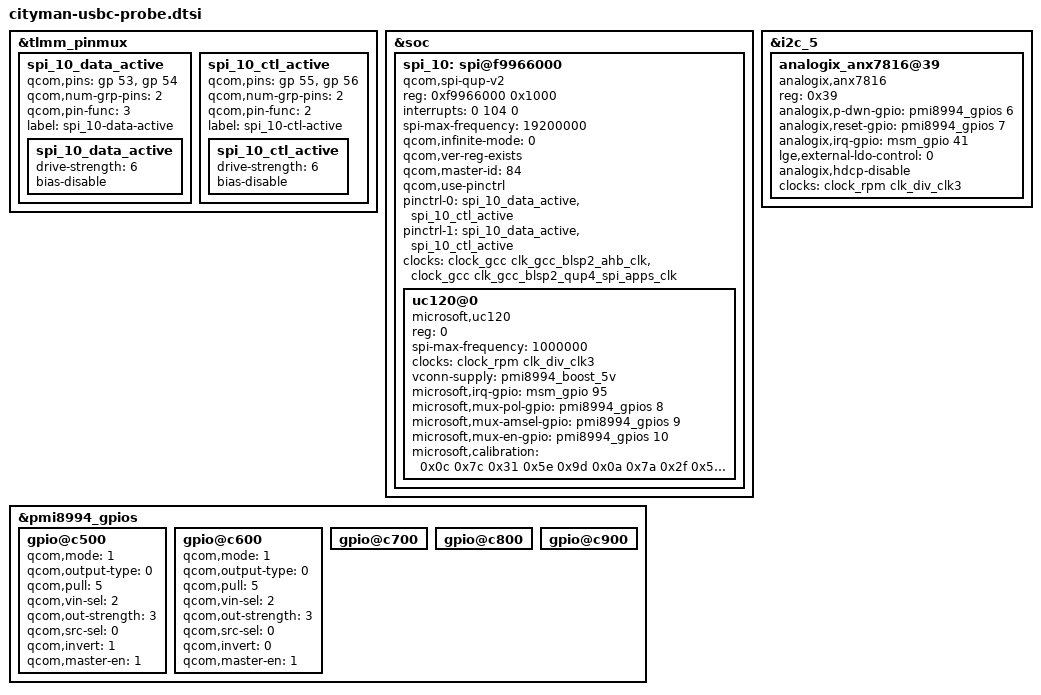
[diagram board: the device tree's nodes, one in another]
/*
 * USB-C path of the Lumia 950 XL, from the Windows SSDT:
 *  - UC120 (Lattice iCE5LP2K, MSHW1006): Type-C/PD PHY on SPI10 CS0,
 *    driven by drivers/misc/uc120.c (charging current, USB host, PD and
 *    DisplayPort alternate mode);
 *  - mux (MSHW1009): PMI8994 GPIO 5, 8, 9, 10;
 *  - Analogix ANX7816 (MSHW1007): HDMI to DisplayPort bridge on I2C11,
 *    power PMI8994 GPIO 6/7.
 * The file name is kept from the first probing branch.
 */

&tlmm_pinmux {
	spi_10_data_active {
		/* MOSI, MISO */
		qcom,pins = <&gp 53>, <&gp 54>;
		qcom,num-grp-pins = <2>;
		qcom,pin-func = <3>;
		label = "spi_10-data-active";
		spi_10_data_active: spi_10_data_active {
			drive-strength = <6>;
			bias-disable;
		};
	};

	spi_10_ctl_active {
		/* CS0, CLK */
		qcom,pins = <&gp 55>, <&gp 56>;
		qcom,num-grp-pins = <2>;
		qcom,pin-func = <2>;
		label = "spi_10-ctl-active";
		spi_10_ctl_active: spi_10_ctl_active {
			drive-strength = <6>;
			bias-disable;
		};
	};
};

&soc {
	spi_10: spi@f9966000 { /* BLSP2 QUP4 */
		compatible = "qcom,spi-qup-v2";
		#address-cells = <1>;
		#size-cells = <0>;
		reg-names = "spi_physical";
		reg = <0xf9966000 0x1000>;
		interrupt-names = "spi_irq";
		interrupts = <0 104 0>;
		spi-max-frequency = <19200000>;
		qcom,infinite-mode = <0>;
		qcom,ver-reg-exists;
		qcom,master-id = <84>;
		qcom,use-pinctrl;
		pinctrl-names = "spi_default", "spi_sleep";
		pinctrl-0 = <&spi_10_data_active &spi_10_ctl_active>;
		pinctrl-1 = <&spi_10_data_active &spi_10_ctl_active>;
		clock-names = "iface_clk", "core_clk";
		clocks = <&clock_gcc clk_gcc_blsp2_ahb_clk>,
			 <&clock_gcc clk_gcc_blsp2_qup4_spi_apps_clk>;

		/*
		 * UC120 Type-C/PD PHY. Calibration: MMO/ice5lp_2k_cal.bin of
		 * the DPP partition (v2 file, bytes 1..10); the driver falls
		 * back to the nominal thresholds without it. IRQ on TLMM 95.
		 * Mux as TypeCMux.sys: PMI8994 GPIO 8 POL, 9 AMSEL, 10 EN.
		 * VCONN from BOOST1_B as the Windows PEP.
		 */
		uc120@0 {
			compatible = "microsoft,uc120";
			reg = <0>;
			spi-max-frequency = <1000000>;
			clock-names = "xtal";
			clocks = <&clock_rpm clk_div_clk3>;
			vconn-supply = <&pmi8994_boost_5v>;
			microsoft,irq-gpio = <&msm_gpio 95 0>;
			microsoft,mux-pol-gpio = <&pmi8994_gpios 8 0>;
			microsoft,mux-amsel-gpio = <&pmi8994_gpios 9 0>;
			microsoft,mux-en-gpio = <&pmi8994_gpios 10 0>;
			microsoft,calibration = /bits/ 8 <0x0c 0x7c 0x31 0x5e 0x9d
							  0x0a 0x7a 0x2f 0x5c 0x9b>;
		};
	};
};

&pmi8994_gpios {
	/*
	 * GPIO 6 and 7 as the Windows PEP drives them for the mux (CPSW):
	 * CMOS output, VIN2 (1.8 V), high strength. Boot in the "USB" state
	 * (P-state 1: GPIO 6 high, GPIO 7 low); the video states turn GPIO 6
	 * low and GPIO 7 high together with PM8994 DIV_CLK3.
	 */
	gpio@c500 {	/* GPIO 6 */
		qcom,mode = <1>;
		qcom,output-type = <0>;
		qcom,pull = <5>;
		qcom,vin-sel = <2>;
		qcom,out-strength = <3>;
		qcom,src-sel = <0>;
		qcom,invert = <1>;	/* constant high */
		qcom,master-en = <1>;
		status = "okay";
	};
	gpio@c600 {	/* GPIO 7: Analogix power/reset */
		qcom,mode = <1>;
		qcom,output-type = <0>;
		qcom,pull = <5>;
		qcom,vin-sel = <2>;
		qcom,out-strength = <3>;
		qcom,src-sel = <0>;
		qcom,invert = <0>;	/* constant low */
		qcom,master-en = <1>;
		status = "okay";
	};
	gpio@c700 { status = "okay"; };	/* GPIO 8: mux */
	gpio@c800 { status = "okay"; };	/* GPIO 9: mux */
	gpio@c900 { status = "okay"; };	/* GPIO 10: mux */
};

/*
 * Analogix ANX7816 SlimPort (HDMI in, DisplayPort out) on I2C11 = i2c_5.
 * Power sequence as the Windows PEP for the mux (CPSW): DIV_CLK3, P_DWN
 * (PMI8994 GPIO 6) low, RESET_N (PMI8994 GPIO 7) high. INTP on TLMM 41.
 * No cable detect pin: the USB-C controller would report the sink.
 */
&i2c_5 {
	analogix_anx7816@39 {
		compatible = "analogix,anx7816";
		reg = <0x39>;
		analogix,p-dwn-gpio = <&pmi8994_gpios 6 0x0>;
		analogix,reset-gpio = <&pmi8994_gpios 7 0x0>;
		analogix,irq-gpio = <&msm_gpio 41 0x0>;
		lge,external-ldo-control = <0>;
		analogix,hdcp-disable;
		clock-names = "xtal";
		clocks = <&clock_rpm clk_div_clk3>;
	};
};
